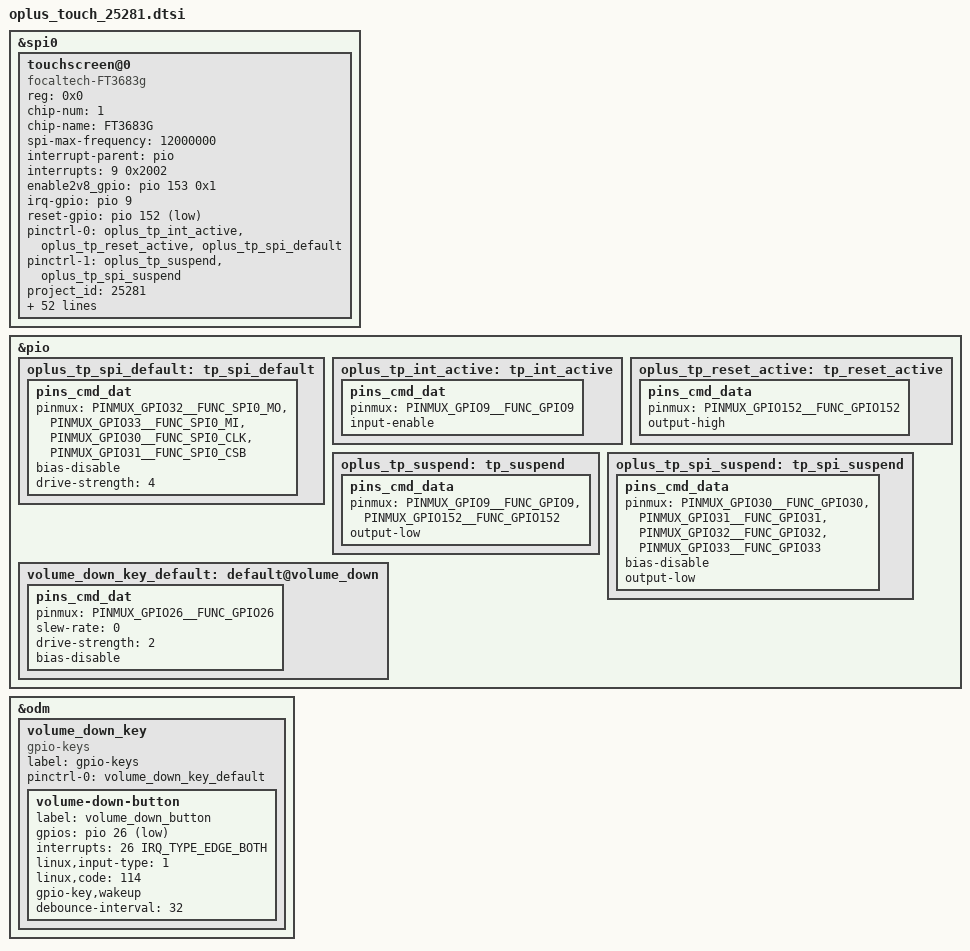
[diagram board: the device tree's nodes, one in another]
&spi0 {
	status = "okay";
	#address-cells = <1>;
	#size-cells = <0>;
	touchscreen@0{
		compatible = "focaltech-FT3683g";
		reg = <0x0>;
		chip-num = <1>;
		chip-name = "FT3683G";
		status = "okay";

		spi-max-frequency = <12000000>;

		/* Interrupt && Irq-gpio */
		interrupt-parent = <&pio>;
		interrupts = <9 0x2002>;

		/* Power Config */
		//vdd_2v8-supply  = <&mt6369_vtp>;
		//vdd_2v8_volt = <3100000>;
		enable2v8_gpio = <&pio 153 0x1>;

		/* Other HW Resource */
		irq-gpio = <&pio 9 0x2002>;
		reset-gpio = <&pio 152 0x1>;

		pinctrl-names = "default",  "sleep";
		pinctrl-0 = <&oplus_tp_int_active &oplus_tp_reset_active &oplus_tp_spi_default>;
		pinctrl-1 = <&oplus_tp_suspend &oplus_tp_spi_suspend>;

		project_id = <25281>;
		touchpanel,max-num-support = <10>;
		touchpanel,tx-rx-num = <18 39>;
		touchpanel,panel-coords = <17280 37952>;
		touchpanel,display-coords = <1080 2372>;
		touchpanel,touchmajor-limit = <128 216>;
		touchpanel,smooth-level = <0 110 115 120 140 155>;
		touchpanel,smooth-level-charging = <0 110 115 120 140 155>;
		touchpanel,sensitive-level = <0 19 16 12 11 10>;
		touchpanel,click-sensitive-level = <0 55 54 52 50 48>;
		touchpanel,tp-index = <0>;
		touchpanel,high-frame-rate-time = <60>;
		touchpanel,single-optimized-time = <8>;

		firmware_name = "AC386BF";
		panel_type = <3>;
		platform_support_project = <25281>;
		platform_support_project_dir = <25281>;
		platform_support_project_commandline = "ac386_p_3_a0025_vdo_panel";

		/* SW Support Feature Control */
		health_monitor_support;
		black_gesture_support;
		charger_pump_support;
		//lcd_tp_refresh_support;
		fw_update_app_support;
		smart_gesture_support;
		game_switch_support;
		report_flow_unlock_support;
		fingerprint_underscreen_support;
		pressure_report_support;
		//report_rate_white_list_support;
		auto_test_force_pass_support;
		snr_read_support;
		//high_resolution_support;
		screenoff_fingerprint_info_support;
		irq_need_dev_resume_ok;
		sportify_aod_gesture_support;
		black_gesture_indep_support;
		thermal_detect_support;
		exception_upload_support;
		tp_data_record_support;
		palm_to_sleep_support;
		glove_mode_v2_support;
		freq_hop_simulate_support;
		fw_edge_limit_support;
		temperature_detect_support;
		temperature_detect_shellback_support;
		disable_touch_event_support;
		fingerprint_not_report_in_suspend;
		fingerprint_error_report_support;
		fp_disable_after_resume;
		idle_freq_support;
		report_rate_v2_support;
		/*
		 *Virtual Key Config:
		 *1:touchpanel,button-type: <virtualkey_type  supportted_button-map>
		 *virtualkey_type:
		 *Type 1: using board_properties
		 *Type 2: using same IC (button zone&& touch zone are seprate)
		 *Type 3: using diffrent IC (button zone&& touch zone are seprate)
		 *Type 4: No need of virtual key process
		 *supportted_button-map:select|menu|home|back
		 *
		 *2:touchpanel,button-map
		 *type (X1,Y1)(X2,Y2)(X3,Y3)(Width_X,Hight_Y)--Only when button-type is 0
		 */
		touchpanel,button-type = <4>;
		touchpanel.button-TRx = <0 0>;
	};
};

&pio {
	oplus_tp_spi_default: tp_spi_default {
		pins_cmd_dat {
			pinmux = <PINMUX_GPIO32__FUNC_SPI0_MO>,
				<PINMUX_GPIO33__FUNC_SPI0_MI>,
				<PINMUX_GPIO30__FUNC_SPI0_CLK>,
				<PINMUX_GPIO31__FUNC_SPI0_CSB>;
			bias-disable;
			drive-strength = <4>;
		};
	};

	oplus_tp_int_active: tp_int_active {
		pins_cmd_dat {
			pinmux = <PINMUX_GPIO9__FUNC_GPIO9>;
			input-enable;
		};
	};

	oplus_tp_reset_active: tp_reset_active {
		pins_cmd_data {
			pinmux = <PINMUX_GPIO152__FUNC_GPIO152>;
			output-high;
		};
	};

	oplus_tp_suspend: tp_suspend {
		pins_cmd_data {
			pinmux = <PINMUX_GPIO9__FUNC_GPIO9>,
					<PINMUX_GPIO152__FUNC_GPIO152>;
			output-low;
		};
	};

	oplus_tp_spi_suspend: tp_spi_suspend {
		pins_cmd_data {
			pinmux = <PINMUX_GPIO30__FUNC_GPIO30>,
					<PINMUX_GPIO31__FUNC_GPIO31>,
					<PINMUX_GPIO32__FUNC_GPIO32>,
					<PINMUX_GPIO33__FUNC_GPIO33>;
			bias-disable;
			output-low;
		};
	};
};

&odm {
	volume_down_key:volume_down_key {
		compatible = "gpio-keys";
		label = "gpio-keys";
		status = "okay";
		pinctrl-0 = <&volume_down_key_default>;
		pinctrl-names = "default";
		volume-down-button {
			label = "volume_down_button";
			gpios = <&pio 26 0x01>;
			interrupts = <26 IRQ_TYPE_EDGE_BOTH>;
			linux,input-type = <1>; /* EV_KEY */
			linux,code = <114>; /* means: KEY_VOLUMEDOWN */
			gpio-key,wakeup;
			debounce-interval = <32>; /* standard debounce time 32ms */
		};
	};
};
&pio {
	volume_down_key_default:default@volume_down {
		pins_cmd_dat {
			pinmux = <PINMUX_GPIO26__FUNC_GPIO26>;
			slew-rate = <0>;
			drive-strength = <2>;
			bias-disable;
		};
	};
};
